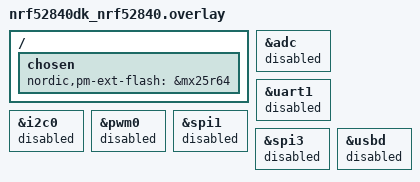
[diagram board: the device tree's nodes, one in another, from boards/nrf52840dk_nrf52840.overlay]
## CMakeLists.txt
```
#
# Copyright (c) 2021 Nordic Semiconductor ASA
#
# SPDX-License-Identifier: LicenseRef-Nordic-5-Clause
#

cmake_minimum_required(VERSION 3.20.0)

find_package(Zephyr HINTS $ENV{ZEPHYR_BASE})

project(matter-template)

# Enable GNU STD support.
include(${ZEPHYR_CONNECTEDHOMEIP_MODULE_DIR}/config/nrfconnect/app/enable-gnu-std.cmake)

# NORDIC SDK APP START

# Include all source files that are located in the Matter common directory.
include(${ZEPHYR_NRF_MODULE_DIR}/samples/matter/common/cmake/source_common.cmake)

# Include Data Model utils
include(${ZEPHYR_NRF_MODULE_DIR}/samples/matter/common/cmake/data_model.cmake)

include(${ZEPHYR_NRF_MODULE_DIR}/samples/matter/common/cmake/zap_helpers.cmake)
ncs_get_zap_parent_dir(ZAP_PARENT_DIR)

target_include_directories(app PRIVATE
    src
    ${ZAP_PARENT_DIR}
)

target_sources(app PRIVATE
    src/app_task.cpp
    src/main.cpp
)

ncs_configure_data_model()
# NORDIC SDK APP END
```

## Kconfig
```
#
# Copyright (c) 2022 Nordic Semiconductor
#
# SPDX-License-Identifier: LicenseRef-Nordic-5-Clause
#
mainmenu "Matter nRF Connect Template Example Application"

# Sample configuration used for Thread networking
if OPENTHREAD

choice OPENTHREAD_NORDIC_LIBRARY_CONFIGURATION
	default OPENTHREAD_NORDIC_LIBRARY_MTD
endchoice

choice OPENTHREAD_DEVICE_TYPE
	default OPENTHREAD_MTD
endchoice

endif # OPENTHREAD

source "${ZEPHYR_CONNECTEDHOMEIP_MODULE_DIR}/config/nrfconnect/chip-module/Kconfig.features"
source "${ZEPHYR_CONNECTEDHOMEIP_MODULE_DIR}/config/nrfconnect/chip-module/Kconfig.defaults"
source "${ZEPHYR_NRF_MODULE_DIR}/samples/matter/common/src/Kconfig"
source "Kconfig.zephyr"
```

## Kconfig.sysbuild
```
#
# Copyright (c) 2023 Nordic Semiconductor ASA
#
# SPDX-License-Identifier: LicenseRef-Nordic-5-Clause
#

config WIFI_NRF70
	default y if BOARD_NRF7002DK

#### Radio core selection
config NRF_DEFAULT_IPC_RADIO
	default y

# Enable IEEE802.15.4 serialization to network core
# This config automatically pulls in the `overlay-802154.conf` in the ipc_radio image
config NETCORE_IPC_RADIO_IEEE802154
	default y if SOC_SERIES_NRF53X && !WIFI_NRF70

# Enable Bluetooth serialization to network core
# This config automatically pulls in the `overlay-bt_hci_ipc.conf` in the ipc_radio image
config NETCORE_IPC_RADIO_BT_HCI_IPC
	default y if SOC_SERIES_NRF53X

#### Bootloader
choice BOOTLOADER
	default BOOTLOADER_MCUBOOT if !BOARD_NRF21540DK
endchoice

if BOOTLOADER_MCUBOOT

#### DFU multi-image support
config DFU_MULTI_IMAGE_PACKAGE_BUILD
	default y

config DFU_MULTI_IMAGE_PACKAGE_APP
	default y

config PM_EXTERNAL_FLASH_MCUBOOT_SECONDARY
	default y

#### DFU network core configuration
if SOC_SERIES_NRF53X

config MCUBOOT_UPDATEABLE_IMAGES
	default 2

choice MCUBOOT_MODE
	default MCUBOOT_MODE_OVERWRITE_ONLY
endchoice

choice BOOT_SIGNATURE_TYPE
	default BOOT_SIGNATURE_TYPE_RSA
endchoice

config SECURE_BOOT_NETCORE
	default y

config NETCORE_APP_UPDATE
	default y

config DFU_MULTI_IMAGE_PACKAGE_NET
	default y

endif # SOC_SERIES_NRF53X

if (BOARD_NRF54L15DK || BOARD_NRF54LM20PDK)

config PM_OVERRIDE_EXTERNAL_DRIVER_CHECK
	default y

endif # (BOARD_NRF54L15DK || BOARD_NRF54LM20PDK)

# Mcuboot padding size is modified to 0x1000 in pm_static file.
if SOC_NRF54L10

config PM_MCUBOOT_PAD
	default 0x1000

endif # SOC_NRF54L10

endif # BOOTLOADER_MCUBOOT

#### Enable generating factory data
config MATTER_FACTORY_DATA_GENERATE
	default y if !BOARD_NRF21540DK

source "share/sysbuild/Kconfig"
```

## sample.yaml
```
sample:
  description: Matter Template sample
  name: Matter Template
common:
  tags:
    - sysbuild
    - ci_samples_matter
tests:
  sample.matter.template.debug:
    sysbuild: true
    build_only: true
    extra_args:
      - CONFIG_NCS_SAMPLE_MATTER_OPERATIONAL_KEYS_MIGRATION_TO_ITS=y
    integration_platforms:
      - nrf52840dk/nrf52840
      - nrf5340dk/nrf5340/cpuapp
      - nrf7002dk/nrf5340/cpuapp
      - nrf54l15dk/nrf54l15/cpuapp
      - nrf54l15dk/nrf54l15/cpuapp/ns
      - nrf54l15dk/nrf54l10/cpuapp
      - nrf54lm20pdk/nrf54lm20a/cpuapp
    platform_allow:
      - nrf52840dk/nrf52840
      - nrf5340dk/nrf5340/cpuapp
      - nrf7002dk/nrf5340/cpuapp
      - nrf54l15dk/nrf54l15/cpuapp
      - nrf54l15dk/nrf54l15/cpuapp/ns
      - nrf54l15dk/nrf54l10/cpuapp
      - nrf54lm20pdk/nrf54lm20a/cpuapp
  sample.matter.template.release:
    sysbuild: true
    build_only: true
    extra_args:
      - FILE_SUFFIX=release
      - CONFIG_NCS_SAMPLE_MATTER_OPERATIONAL_KEYS_MIGRATION_TO_ITS=y
    integration_platforms:
      - nrf52840dk/nrf52840
      - nrf5340dk/nrf5340/cpuapp
      - nrf7002dk/nrf5340/cpuapp
      - nrf54l15dk/nrf54l15/cpuapp
      - nrf54l15dk/nrf54l15/cpuapp/ns
      - nrf54l15dk/nrf54l10/cpuapp
      - nrf54lm20pdk/nrf54lm20a/cpuapp
    platform_allow:
      - nrf52840dk/nrf52840
      - nrf5340dk/nrf5340/cpuapp
      - nrf7002dk/nrf5340/cpuapp
      - nrf54l15dk/nrf54l15/cpuapp
      - nrf54l15dk/nrf54l15/cpuapp/ns
      - nrf54l15dk/nrf54l10/cpuapp
      - nrf54lm20pdk/nrf54lm20a/cpuapp
  sample.matter.template.smp_dfu:
    sysbuild: true
    build_only: true
    extra_args:
      - CONFIG_CHIP_DFU_OVER_BT_SMP=y
      - CONFIG_NCS_SAMPLE_MATTER_OPERATIONAL_KEYS_MIGRATION_TO_ITS=y
    integration_platforms:
      - nrf52840dk/nrf52840
      - nrf5340dk/nrf5340/cpuapp
      - nrf7002dk/nrf5340/cpuapp
      - nrf54l15dk/nrf54l15/cpuapp
      - nrf54l15dk/nrf54l15/cpuapp/ns
      - nrf54l15dk/nrf54l10/cpuapp
      - nrf54lm20pdk/nrf54lm20a/cpuapp
    platform_allow:
      - nrf52840dk/nrf52840
      - nrf5340dk/nrf5340/cpuapp
      - nrf7002dk/nrf5340/cpuapp
      - nrf54l15dk/nrf54l15/cpuapp
      - nrf54l15dk/nrf54l15/cpuapp/ns
      - nrf54l15dk/nrf54l10/cpuapp
      - nrf54lm20pdk/nrf54lm20a/cpuapp
  sample.matter.template.release.internal:
    sysbuild: true
    build_only: true
    extra_args:
      - FILE_SUFFIX=internal
      - template_EXTRA_CONF_FILE=prj_release.conf
    integration_platforms:
      - nrf54l15dk/nrf54l15/cpuapp
      - nrf54lm20pdk/nrf54lm20a/cpuapp
    platform_allow:
      - nrf54l15dk/nrf54l15/cpuapp
      - nrf54lm20pdk/nrf54lm20a/cpuapp
  sample.matter.template.release.internal.smp_dfu:
    sysbuild: true
    build_only: true
    extra_args:
      - FILE_SUFFIX=internal
      - CONFIG_CHIP_DFU_OVER_BT_SMP=y
      - template_EXTRA_CONF_FILE=prj_release.conf
    integration_platforms:
      - nrf54l15dk/nrf54l15/cpuapp
      - nrf54lm20pdk/nrf54lm20a/cpuapp
    platform_allow:
      - nrf54l15dk/nrf54l15/cpuapp
      - nrf54lm20pdk/nrf54lm20a/cpuapp
  sample.matter.template.cc3xx_backend:
    sysbuild: true
    build_only: true
    extra_args:
      - CONFIG_PSA_CRYPTO_DRIVER_CC3XX=y
    integration_platforms:
      - nrf52840dk/nrf52840
      - nrf5340dk/nrf5340/cpuapp
    platform_allow:
      - nrf52840dk/nrf52840
      - nrf5340dk/nrf5340/cpuapp
  sample.matter.template.smp_dfu.old_ec:
    sysbuild: true
    build_only: true
    extra_args:
      - CONFIG_CHIP_DFU_OVER_BT_SMP=y
      - SB_CONFIG_BOOT_SIGNATURE_TYPE_RSA=y
      - CONFIG_SETTINGS_ZMS_LEGACY=y
    integration_platforms:
      - nrf54l15dk/nrf54l15/cpuapp
    platform_allow:
      - nrf54l15dk/nrf54l15/cpuapp
  sample.matter.template.certification:
    sysbuild: true
    build_only: true
    extra_args:
      - CONFIG_NCS_SAMPLE_MATTER_CERTIFICATION=y
      - OVERLAY_CONFIG="../common/src/certification/thread_platform/overlay-thread_platform.conf"
      - template_SNIPPET="diagnostic-logs;matter-debug"
    integration_platforms:
      - nrf52840dk/nrf52840
      - nrf5340dk/nrf5340/cpuapp
      - nrf54l15dk/nrf54l15/cpuapp
      - nrf54lm20pdk/nrf54lm20a/cpuapp
    platform_allow:
      - nrf52840dk/nrf52840
      - nrf5340dk/nrf5340/cpuapp
      - nrf54l15dk/nrf54l15/cpuapp
      - nrf54lm20pdk/nrf54lm20a/cpuapp
```

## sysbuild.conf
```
#
# Copyright (c) 2024 Nordic Semiconductor
#
# SPDX-License-Identifier: LicenseRef-Nordic-5-Clause
#

SB_CONFIG_MATTER=y
```

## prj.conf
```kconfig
#
# Copyright (c) 2021 Nordic Semiconductor ASA
#
# SPDX-License-Identifier: LicenseRef-Nordic-5-Clause
#

# This sample uses Kconfig.defaults to set options common for all
# samples. This file should contain only options specific for this sample
# or overrides of default values.

# Enable CHIP
CONFIG_CHIP=y
CONFIG_CHIP_PROJECT_CONFIG="src/chip_project_config.h"

# Configure ZAP file name
CONFIG_NCS_SAMPLE_MATTER_ZAP_FILE_PATH="${APPLICATION_CONFIG_DIR}/src/default_zap/template.zap"

# 32768 == 0x8000 (example Product ID added temporaly,
# but it must be changed with proper PID from the list:
# https://github.com/project-chip/connectedhomeip/blob/482e6fd03196a6de45465a90003947ef4b86e0b1/docs/examples/discussion/PID_allocation_for_example_apps.md)
CONFIG_CHIP_DEVICE_PRODUCT_ID=32768
CONFIG_STD_CPP17=y

# Enable Matter pairing automatically on application start.
CONFIG_CHIP_ENABLE_PAIRING_AUTOSTART=y

# Enable Matter extended announcement and increase duration to 1 hour.
CONFIG_CHIP_BLE_EXT_ADVERTISING=y
CONFIG_CHIP_BLE_ADVERTISING_DURATION=60

# Add support for LEDs and buttons on Nordic development kits
CONFIG_DK_LIBRARY=y

# Bluetooth Low Energy configuration
CONFIG_BT_DEVICE_NAME="MatterTemplate"

# Other settings
CONFIG_THREAD_NAME=y
CONFIG_MPU_STACK_GUARD=y
CONFIG_RESET_ON_FATAL_ERROR=n
CONFIG_CHIP_LIB_SHELL=y
CONFIG_NCS_SAMPLE_MATTER_TEST_SHELL=y

# Disable NFC onboarding
CONFIG_CHIP_NFC_ONBOARDING_PAYLOAD=n

# Reduce application size
CONFIG_USE_SEGGER_RTT=n

# Enable Factory Data feature
CONFIG_CHIP_FACTORY_DATA=y
CONFIG_CHIP_FACTORY_DATA_BUILD=y
```

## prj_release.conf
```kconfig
#
# Copyright (c) 2021 Nordic Semiconductor ASA
#
# SPDX-License-Identifier: LicenseRef-Nordic-5-Clause
#

# This sample uses Kconfig.defaults to set options common for all
# samples. This file should contain only options specific for this sample
# or overrides of default values.

# Enable CHIP
CONFIG_CHIP=y
CONFIG_CHIP_PROJECT_CONFIG="src/chip_project_config.h"

# Configure ZAP file name
CONFIG_NCS_SAMPLE_MATTER_ZAP_FILE_PATH="${APPLICATION_CONFIG_DIR}/src/default_zap/template.zap"

# 32768 == 0x8000 (example Product ID added temporaly,
# but it must be changed with proper PID from the list:
# https://github.com/project-chip/connectedhomeip/blob/482e6fd03196a6de45465a90003947ef4b86e0b1/docs/examples/discussion/PID_allocation_for_example_apps.md)
CONFIG_CHIP_DEVICE_PRODUCT_ID=32768
CONFIG_STD_CPP17=y

# Enable Matter pairing automatically on application start.
CONFIG_CHIP_ENABLE_PAIRING_AUTOSTART=y

# Enable Matter extended announcement and increase duration to 1 hour.
CONFIG_CHIP_BLE_EXT_ADVERTISING=y
CONFIG_CHIP_BLE_ADVERTISING_DURATION=60

# Add support for LEDs and buttons on Nordic development kits
CONFIG_DK_LIBRARY=y

# Bluetooth Low Energy configuration
CONFIG_BT_DEVICE_NAME="MatterTemplate"

# Enable system reset on fatal error
CONFIG_RESET_ON_FATAL_ERROR=y

# Disable all debug features
CONFIG_USE_SEGGER_RTT=n
CONFIG_SHELL=n
CONFIG_OPENTHREAD_SHELL=n
CONFIG_CHIP_LIB_SHELL=n
CONFIG_CONSOLE=n
CONFIG_UART_CONSOLE=n
CONFIG_SERIAL=n
CONFIG_LOG=n
CONFIG_LOG_MODE_MINIMAL=n
CONFIG_ASSERT_VERBOSE=n
CONFIG_ASSERT_NO_FILE_INFO=y
CONFIG_PRINTK=n
CONFIG_PRINTK_SYNC=n
CONFIG_THREAD_NAME=n
CONFIG_BOOT_BANNER=n

# Disable NFC onboarding
CONFIG_CHIP_NFC_ONBOARDING_PAYLOAD=n

# Enable Factory Data feature
CONFIG_CHIP_FACTORY_DATA=y
CONFIG_CHIP_FACTORY_DATA_BUILD=y

# Enable Watchdog
CONFIG_NCS_SAMPLE_MATTER_WATCHDOG=y

# Enable LTO to decrease the flash usage.
CONFIG_LTO=y
CONFIG_ISR_TABLES_LOCAL_DECLARATION=y
```

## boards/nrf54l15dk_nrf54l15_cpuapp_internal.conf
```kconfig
#
# Copyright (c) 2024 Nordic Semiconductor ASA
#
# SPDX-License-Identifier: LicenseRef-Nordic-5-Clause
#

# Disable SPI
CONFIG_CHIP_SPI_NOR=n

# Enable Watchdog
CONFIG_NCS_SAMPLE_MATTER_WATCHDOG=y

# Enable LTO to decrease the flash usage.
CONFIG_LTO=y
CONFIG_ISR_TABLES_LOCAL_DECLARATION=y
```

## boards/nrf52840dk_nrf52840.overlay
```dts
/* Copyright (c) 2021 Nordic Semiconductor ASA
 *
 * SPDX-License-Identifier: LicenseRef-Nordic-5-Clause
 */

/ {
	chosen {
		nordic,pm-ext-flash = &mx25r64;
	};
};

/* Disable unused peripherals to reduce power consumption */
&adc {
	status = "disabled";
};
&uart1 {
	status = "disabled";
};
&i2c0 {
	status = "disabled";
};
&pwm0 {
	status = "disabled";
};
&spi1 {
	status = "disabled";
};
&spi3 {
	status = "disabled";
};
&usbd {
	status = "disabled";
};
```

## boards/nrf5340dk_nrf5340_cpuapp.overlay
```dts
/*
 * Copyright (c) 2021 Nordic Semiconductor ASA
 *
 * SPDX-License-Identifier: LicenseRef-Nordic-5-Clause
 */

#include <zephyr/dt-bindings/ipc_service/static_vrings.h>

/ {
	chosen {
		nordic,pm-ext-flash = &mx25r64;
	};
};

/* Set IPC thread priority to the highest value to not collide with other threads. */
&ipc0 {
	zephyr,priority = <0 PRIO_COOP>;
};

/* Disable unused peripherals to reduce power consumption */
&adc {
	status = "disabled";
};
&i2c1 {
	status = "disabled";
};
&pwm0 {
	status = "disabled";
};
&spi2 {
	status = "disabled";
};
&usbd {
	status = "disabled";
};
```

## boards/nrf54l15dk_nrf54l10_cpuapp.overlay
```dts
/*
 * Copyright (c) 2024 Nordic Semiconductor ASA
 *
 * SPDX-License-Identifier: LicenseRef-Nordic-5-Clause
 */

/ {
	aliases {
		// Use watchdog wdt31 as the application watchdog
		watchdog0 = &wdt31;
	};

	chosen {
		nordic,pm-ext-flash = &mx25r64;
	};
};

// restore full RRAM and SRAM space - by default some parts are dedicated to FLRP
&cpuapp_rram {
	reg = <0x0 DT_SIZE_K(1022)>;
};

&cpuapp_sram {
	reg = <0x20000000 DT_SIZE_K(192)>;
	ranges = <0x0 0x20000000  DT_SIZE_K(192)>;
};

// TODO: re-enable HWFC once it's fixed
&uart20 {
	/delete-property/ hw-flow-control;
};

&mx25r64 {
	status = "okay";
};

&wdt31 {
	status = "okay";
};
```

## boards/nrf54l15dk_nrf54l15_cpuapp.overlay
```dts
/*
 * Copyright (c) 2024 Nordic Semiconductor ASA
 *
 * SPDX-License-Identifier: LicenseRef-Nordic-5-Clause
 */

/ {
	aliases {
		// Use watchdog wdt31 as the application watchdog
		watchdog0 = &wdt31;
	};

	chosen {
		nordic,pm-ext-flash = &mx25r64;
	};
};

// restore full RRAM and SRAM space - by default some parts are dedicated to FLRP
&cpuapp_rram {
	reg = <0x0 DT_SIZE_K(1524)>;
};

&cpuapp_sram {
	reg = <0x20000000 DT_SIZE_K(256)>;
	ranges = <0x0 0x20000000  0x40000>;
};

// TODO: re-enable HWFC once it's fixed
&uart20 {
	/delete-property/ hw-flow-control;
};

&mx25r64 {
	status = "okay";
};

&wdt31 {
	status = "okay";
};
```

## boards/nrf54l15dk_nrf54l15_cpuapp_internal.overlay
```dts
/*
 * Copyright (c) 2024 Nordic Semiconductor ASA
 *
 * SPDX-License-Identifier: LicenseRef-Nordic-5-Clause
 */

/ {
	aliases {
		// Use watchdog wdt31 as the application watchdog
		watchdog0 = &wdt31;
	};
};

// restore full RRAM and SRAM space - by default some parts are dedicated to FLRP
&cpuapp_rram {
	reg = <0x0 DT_SIZE_K(1524)>;
};

&cpuapp_sram {
	reg = <0x20000000 DT_SIZE_K(256)>;
	ranges = <0x0 0x20000000  0x40000>;
};

// TODO: re-enable HWFC once it's fixed
&uart20 {
	/delete-property/ hw-flow-control;
};

&mx25r64 {
	status = "disabled";
};

&wdt31 {
	status = "okay";
};
```

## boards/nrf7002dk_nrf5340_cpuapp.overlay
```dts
/*
 * Copyright (c) 2021 Nordic Semiconductor ASA
 *
 * SPDX-License-Identifier: LicenseRef-Nordic-5-Clause
 */

#include <zephyr/dt-bindings/ipc_service/static_vrings.h>

/ {
	chosen {
		nordic,pm-ext-flash = &mx25r64;
	};

	aliases {
		watchdog0 = &wdt0;
	};

};

/* Set IPC thread priority to the highest value to not collide with other threads. */
&ipc0 {
	zephyr,priority = <0 PRIO_COOP>;
};
```

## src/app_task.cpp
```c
/*
 * Copyright (c) 2021 Nordic Semiconductor ASA
 *
 * SPDX-License-Identifier: LicenseRef-Nordic-5-Clause
 */

#include "app_task.h"

#include "app/matter_init.h"
#include "app/task_executor.h"
#include "board/board.h"
#include "lib/core/CHIPError.h"
#include "lib/support/CodeUtils.h"

#include <setup_payload/OnboardingCodesUtil.h>

#include <zephyr/logging/log.h>

LOG_MODULE_DECLARE(app, CONFIG_CHIP_APP_LOG_LEVEL);

using namespace ::chip;
using namespace ::chip::app;
using namespace ::chip::DeviceLayer;

CHIP_ERROR AppTask::Init()
{
	/* Initialize Matter stack */
	ReturnErrorOnFailure(Nrf::Matter::PrepareServer());

	if (!Nrf::GetBoard().Init()) {
		LOG_ERR("User interface initialization failed.");
		return CHIP_ERROR_INCORRECT_STATE;
	}

	/* Register Matter event handler that controls the connectivity status LED based on the captured Matter network
	 * state. */
	ReturnErrorOnFailure(Nrf::Matter::RegisterEventHandler(Nrf::Board::DefaultMatterEventHandler, 0));

	return Nrf::Matter::StartServer();
}

CHIP_ERROR AppTask::StartApp()
{
	ReturnErrorOnFailure(Init());

	while (true) {
		Nrf::DispatchNextTask();
	}

	return CHIP_NO_ERROR;
}
```

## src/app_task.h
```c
/*
 * Copyright (c) 2021 Nordic Semiconductor ASA
 *
 * SPDX-License-Identifier: LicenseRef-Nordic-5-Clause
 */

#pragma once

#include <platform/CHIPDeviceLayer.h>

struct k_timer;

class AppTask {
public:
	static AppTask &Instance()
	{
		static AppTask sAppTask;
		return sAppTask;
	};

	CHIP_ERROR StartApp();

private:
	CHIP_ERROR Init();
};
```
